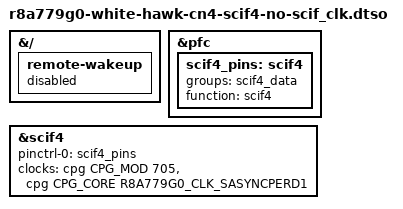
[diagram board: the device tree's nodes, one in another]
// SPDX-License-Identifier: (GPL-2.0-only OR BSD-2-Clause)
//
// Device Tree Overlay for SCIF4 without SCIF_CLK on White Hawk GPIO CN CN4
//
// Copyright (C) 2024 Glider bv
//
// Pinout:
//   - TXD  = CN4 pin 6
//   - RXD  = CN4 pin 8
//
//   - GND  = CN4 pin 3/4/7/11
//
//  Notes:
//    - As GP8_12 might be used for remote-wakeup, the latter must be disabled
//	first, if enabled.

/dts-v1/;
/plugin/;

#include <dt-bindings/clock/r8a779g0-cpg-mssr.h>

&{/} {
	remote-wakeup {
		status = "disabled";
	};
};

&pfc {
	scif4_pins: scif4 {
		groups = "scif4_data";
		function = "scif4";
	};
};

&scif4 {
	pinctrl-0 = <&scif4_pins>;
	pinctrl-names = "default";

	clocks = <&cpg CPG_MOD 705>, <&cpg CPG_CORE R8A779G0_CLK_SASYNCPERD1>;
	clock-names = "fck", "brg_int";
	status = "okay";
};
